# tviibh16m register map
Vendor: Infineon Technologies; Series: TVIIBH16M; File version: 1.0
CPU: CM7 r0p1, little endian, MPU, FPU, double-precision FPU, I-cache, D-cache, VTOR, ITCM, DTCM, 3 interrupt priority bits, 16 interrupts
Registers are 32-bit, read-write, reset 0x0 unless marked. A register's access mark holds for its fields unless they carry their own. Offsets are from the block's base; [hi:lo] are bit positions; lines under a group give offsets from that group; {n}, {i} and the like mark numbered series; 'fields as' and 'values as' point back to an identical list.

## IPC
Base 0x40220000
{0x0+0x20*i} STRUCT[{i}] (i=0..15) group — IPC structure
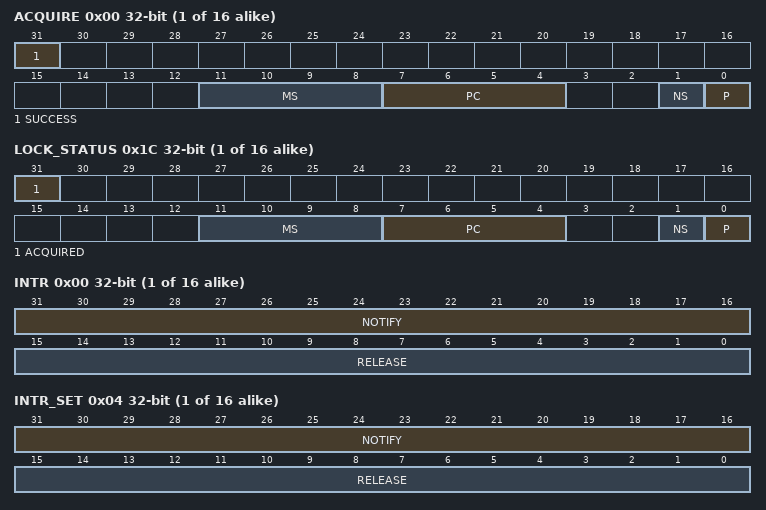
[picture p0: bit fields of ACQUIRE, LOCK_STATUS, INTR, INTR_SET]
  0x00 ACQUIRE ro (reset mask 0x80000000) — IPC acquire
    [31] SUCCESS — Specifies if the lock is successfully acquired or not (reading the ACQUIRE register can have affect on SUCCESS and LOCK_STATUS.ACQUIRED): '0': Not successfully acquired; i.e. the lock was already acquired by another read transaction and not released. The P, NS, PC and MS fields reflect the access attributes of the transaction that previously successfully acuired the lock; the fields are NOT affected by the current access. '1': Successfully acquired. The P, NS, PC and MS fields reflect the access attributes of the current access. Note that this field is NOT SW writable. A lock is released by writing to the associated RELEASE register (irrespective of the write value).
    [11:8] MS — This field specifies the bus master identifier that successfully acquired the lock.
    [7:4] PC — This field specifies the protection context that successfully acquired the lock.
    [1] NS — Secure/non-secure access control: '0': secure. '1': non-secure. This field is set with the secure/non-secure access control of the access that successfully acquired the lock.
    [0] P — User/privileged access control: '0': user mode. '1': privileged mode. This field is set with the user/privileged access control of the access that successfully acquired the lock.
  0x04 RELEASE wo — IPC release
    [15:0] INTR_RELEASE — Writing this field releases a lock and allows for the generation of release events to the IPC interrupt structures, but only when the lock is acquired (LOCK_STATUS.ACQUIRED is '1'). The IPC release cause fields associated with this IPC structure are set to '1', but only for those IPC interrupt structures for which the corresponding bit field in INTR_RELEASE[] is set to '1'. SW writes a '1' to the bit fields to generate a release event. Due to the transient nature of this event, SW always reads a '0' from this field.
  0x08 NOTIFY wo — IPC notification
    [15:0] INTR_NOTIFY — This field allows for the generation of notification events to the IPC interrupt structures. The IPC notification cause fields associated with this IPC structure are set to '1', but only for those IPC interrupt structures for which the corresponding bit field in INTR_NOTIFY[] is set to '1'. SW writes a '1' to the bit fields to generate a notify event. Due to the transient nature of this event, SW always reads a '0' from this field.
  0x0C DATA0 reset not defined — IPC data 0
    [31:0] DATA — This field holds a 32-bit data element that is associated with the IPC structure.
  0x10 DATA1 reset not defined — IPC data 1
    fields as STRUCT[0].DATA0
  0x1C LOCK_STATUS ro (reset mask 0x80000000) — IPC lock status
    [31] ACQUIRED — Specifies if the lock is acquired. This field is set to '1', if a ACQUIRE read transfer successfully acquires the lock (the ACQUIRE read transfer returns ACQUIRE.SUCCESS as '1'). If zero, P, NS, PC, and MS are not valid.
    [11:8] MS — This field specifies the bus master identifier that successfully acquired the lock.
    [7:4] PC — This field specifies the protection context that successfully acquired the lock.
    [1] NS — This field specifies the secure/non-secure access control: '0': secure. '1': non-secure.
    [0] P — This field specifies the user/privileged access control: '0': user mode. '1': privileged mode.
{0x1000+0x20*i} INTR_STRUCT[{i}] (i=0..15) group — IPC interrupt structure
  0x00 INTR — Interrupt
    [31:16] NOTIFY write-1-clears — These interrupt cause fields are activated (HW sets the field to '1') when a IPC notification event is detected. One bit field for each master. SW writes a '1' to these field to clear the interrupt cause.
    [15:0] RELEASE write-1-clears — These interrupt cause fields are activated (HW sets the field to '1') when a IPC release event is detected. One bit field for each master. SW writes a '1' to these field to clear the interrupt cause.
  0x04 INTR_SET — Interrupt set
    [31:16] NOTIFY write-1-sets — SW writes a '1' to this field to set the corresponding field in the INTR register.
    [15:0] RELEASE write-1-sets — SW writes a '1' to this field to set the corresponding field in the INTR register.
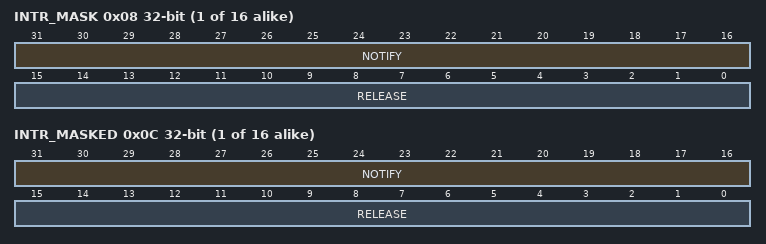
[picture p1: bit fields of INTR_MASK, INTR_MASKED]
  0x08 INTR_MASK — Interrupt mask
    [31:16] NOTIFY — Mask bit for corresponding field in the INTR register.
    [15:0] RELEASE — Mask bit for corresponding field in the INTR register.
  0x0C INTR_MASKED ro — Interrupt masked
    [31:16] NOTIFY — Logical and of corresponding INTR and INTR_MASK fields.
    [15:0] RELEASE — Logical and of corresponding request and mask bits.
